# MKW21Z4 register map
Vendor: Freescale Semiconductor, Inc.; Series: Kinetis_W; File version: 1.6
CPU: CM0PLUS r0p0, little endian, no MPU, no FPU, VTOR, 2 interrupt priority bits
Registers are 16-bit, read-write, no defined reset value unless marked. A register's access mark holds for its fields unless they carry their own. Offsets are from the block's base; [hi:lo] are bit positions.

## RTC — Secure Real Time Clock
Base 0x4003D000; register names take the prefix RTC_
0x00 TSR 32-bit reset 0x0 — RTC Time Seconds Register
  [31:0] TSR — Time Seconds Register
0x04 TPR 32-bit reset 0x0 — RTC Time Prescaler Register
  [15:0] TPR — Time Prescaler Register
0x08 TAR 32-bit reset 0x0 — RTC Time Alarm Register
  [31:0] TAR — Time Alarm Register
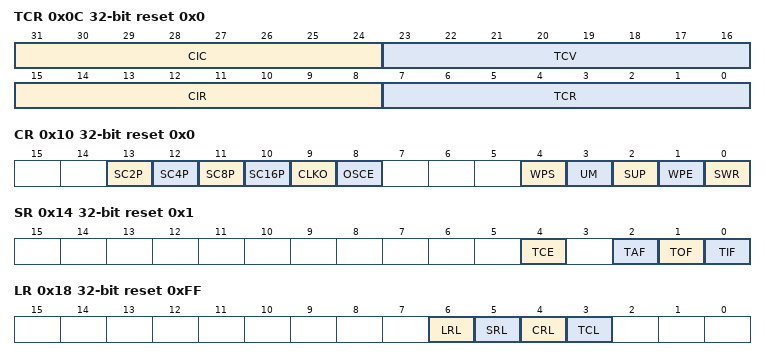
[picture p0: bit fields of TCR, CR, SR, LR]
0x0C TCR 32-bit reset 0x0 — RTC Time Compensation Register
  [31:24] CIC ro — Compensation Interval Counter
  [23:16] TCV ro — Time Compensation Value
  [15:8] CIR — Compensation Interval Register
  [7:0] TCR — Time Compensation Register
    128=Time Prescaler Register overflows every 32896 clock cycles; 255=Time Prescaler Register overflows every 32769 clock cycles; 0=Time Prescaler Register overflows every 32768 clock cycles; 1=Time Prescaler Register overflows every 32767 clock cycles; 127=Time Prescaler Register overflows every 32641 clock cycles
0x10 CR 32-bit reset 0x0 — RTC Control Register
  [13] SC2P — Oscillator 2pF Load Configure
    0=Disable the load; 1=Enable the additional load
  [12] SC4P — Oscillator 4pF Load Configure
    0=Disable the load; 1=Enable the additional load
  [11] SC8P — Oscillator 8pF Load Configure
    0=Disable the load; 1=Enable the additional load
  [10] SC16P — Oscillator 16pF Load Configure
    0=Disable the load; 1=Enable the additional load
  [9] CLKO — Clock Output
    0=The 32 kHz clock is output to other peripherals; 1=The 32 kHz clock is not output to other peripherals
  [8] OSCE — Oscillator Enable
    0=32.768 kHz oscillator is disabled; 1=32.768 kHz oscillator is enabled. After setting this bit, wait the oscillator startup time before enabling the time counter to allow the 32.768 kHz clock time to stabilize.
  [4] WPS — Wakeup Pin Select
    0=Wakeup pin asserts (active low, open drain) if the RTC interrupt asserts or the wakeup pin is turned on; 1=Wakeup pin instead outputs the RTC 32kHz clock, provided the wakeup pin is turned on and the 32kHz clock is output to other peripherals
  [3] UM — Update Mode
    0=Registers cannot be written when locked; 1=Registers can be written when locked under limited conditions
  [2] SUP — Supervisor Access
    0=Non-supervisor mode write accesses are not supported and generate a bus error; 1=Non-supervisor mode write accesses are supported
  [1] WPE — Wakeup Pin Enable
    0=Wakeup pin is disabled; 1=Wakeup pin is enabled and wakeup pin asserts if the RTC interrupt asserts or the wakeup pin is turned on
  [0] SWR — Software Reset
    0=No effect; 1=Resets all RTC registers except for the SWR bit . The SWR bit is cleared by POR and by software explicitly clearing it.
0x14 SR 32-bit reset 0x1 — RTC Status Register
  [4] TCE — Time Counter Enable
    0=Time counter is disabled; 1=Time counter is enabled
  [2] TAF ro — Time Alarm Flag
    0=Time alarm has not occurred; 1=Time alarm has occurred
  [1] TOF ro — Time Overflow Flag
    0=Time overflow has not occurred; 1=Time overflow has occurred and time counter is read as zero
  [0] TIF ro — Time Invalid Flag
    0=Time is valid; 1=Time is invalid and time counter is read as zero
0x18 LR 32-bit reset 0xFF — RTC Lock Register
  [6] LRL — Lock Register Lock
    0=Lock Register is locked and writes are ignored; 1=Lock Register is not locked and writes complete as normal
  [5] SRL — Status Register Lock
    0=Status Register is locked and writes are ignored; 1=Status Register is not locked and writes complete as normal
  [4] CRL — Control Register Lock
    0=Control Register is locked and writes are ignored; 1=Control Register is not locked and writes complete as normal
  [3] TCL — Time Compensation Lock
    0=Time Compensation Register is locked and writes are ignored; 1=Time Compensation Register is not locked and writes complete as normal
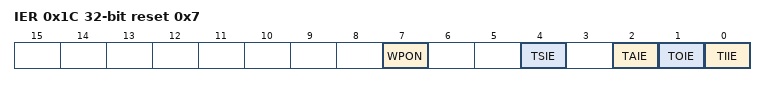
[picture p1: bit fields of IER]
0x1C IER 32-bit reset 0x7 — RTC Interrupt Enable Register
  [7] WPON — Wakeup Pin On
    0=No effect; 1=If the wakeup pin is enabled, then the wakeup pin will assert
  [4] TSIE — Time Seconds Interrupt Enable
    0=Seconds interrupt is disabled; 1=Seconds interrupt is enabled
  [2] TAIE — Time Alarm Interrupt Enable
    0=Time alarm flag does not generate an interrupt; 1=Time alarm flag does generate an interrupt
  [1] TOIE — Time Overflow Interrupt Enable
    0=Time overflow flag does not generate an interrupt; 1=Time overflow flag does generate an interrupt
  [0] TIIE — Time Invalid Interrupt Enable
    0=Time invalid flag does not generate an interrupt; 1=Time invalid flag does generate an interrupt

## Notices in the file
Redistribution and use in source and binary forms, with or without modification,
are permitted provided that the following conditions are met:
o Redistributions of source code must retain the above copyright notice, this list
of conditions and the following disclaimer.
o Redistributions in binary form must reproduce the above copyright notice, this
list of conditions and the following disclaimer in the documentation and/or
other materials provided with the distribution.
o Neither the name of Freescale Semiconductor, Inc. nor the names of its
contributors may be used to endorse or promote products derived from this
software without specific prior written permission.
THIS SOFTWARE IS PROVIDED BY THE COPYRIGHT HOLDERS AND CONTRIBUTORS "AS IS" AND
ANY EXPRESS OR IMPLIED WARRANTIES, INCLUDING, BUT NOT LIMITED TO, THE IMPLIED
WARRANTIES OF MERCHANTABILITY AND FITNESS FOR A PARTICULAR PURPOSE ARE
DISCLAIMED. IN NO EVENT SHALL THE COPYRIGHT HOLDER OR CONTRIBUTORS BE LIABLE FOR
ANY DIRECT, INDIRECT, INCIDENTAL, SPECIAL, EXEMPLARY, OR CONSEQUENTIAL DAMAGES
(INCLUDING, BUT NOT LIMITED TO, PROCUREMENT OF SUBSTITUTE GOODS OR SERVICES;
LOSS OF USE, DATA, OR PROFITS; OR BUSINESS INTERRUPTION) HOWEVER CAUSED AND ON
ANY THEORY OF LIABILITY, WHETHER IN CONTRACT, STRICT LIABILITY, OR TORT
(INCLUDING NEGLIGENCE OR OTHERWISE) ARISING IN ANY WAY OUT OF THE USE OF THIS
SOFTWARE, EVEN IF ADVISED OF THE POSSIBILITY OF SUCH DAMAGE.
